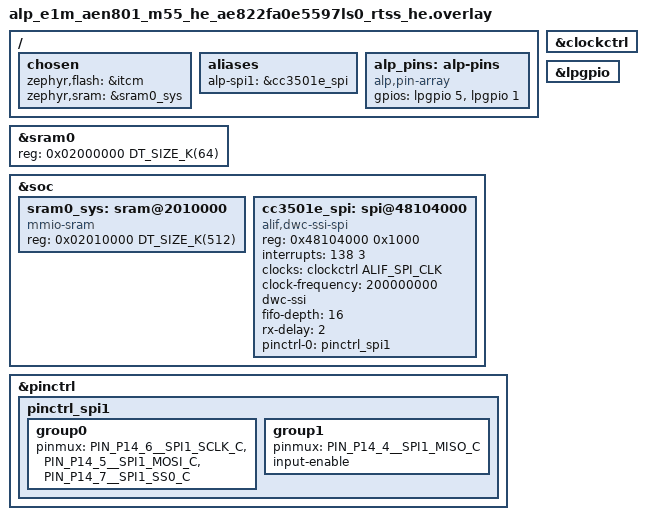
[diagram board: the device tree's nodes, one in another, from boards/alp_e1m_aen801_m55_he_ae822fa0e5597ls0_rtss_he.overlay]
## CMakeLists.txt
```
# SPDX-License-Identifier: Apache-2.0
#
# aen-cc3501e-silent-scan-probe -- tests whether a WIFI_SCAN_START submit
# survives 25 seconds of a completely silent host bus, on the
# E1M-AEN801 (Ensemble E8, M55-HE) bench.
#
# Standalone Zephyr app (no alp_project.py board.yaml flow): build with
#   ZEPHYR_BASE=<zephyr-base> west build \
#     -b alp_e1m_aen801_m55_he/ae822fa0e5597ls0/rtss_he <this-dir> -- \
#     "-DEXTRA_ZEPHYR_MODULES=<alp-sdk>;<hal_alif>"
# Zephyr applies boards/<fully-qualified-board>.overlay by itself.

cmake_minimum_required(VERSION 3.20)

find_package(Zephyr REQUIRED HINTS $ENV{ZEPHYR_BASE})
project(aen_cc3501e_silent_scan_probe LANGUAGES C)

target_sources(app PRIVATE src/main.c)
# The SoM bring-up TEMPLATE (see its own header comment): opens the
# inter-chip SPI1 bridge + WIFI_EN/nRESET, enables the LP-pad output
# drivers pinctrl does not reach, binds the READY line, and runs the
# power + reset sequence. Copied verbatim from aen-cc3501e-command-sweep --
# byte-identical to the copies in every aen-cc3501e-* sibling, same
# reasoning: a copyable template, not a cross-example reach-in.
target_sources(app PRIVATE src/cc3501e_bridge.c)
```

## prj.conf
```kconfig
# SPDX-License-Identifier: Apache-2.0
#
# Bench config for the CC3501E silent-scan probe on the E1M-AEN801 (Alif
# Ensemble E8, M55-HE). See src/main.c for what this app does and why.

# --- Console -----------------------------------------------------------------
# Console: Alp UART console -- E1M edge UART0 (Alif UART5, P3_4/P3_5, 115200
# 8N1, NS16550), the E1M-AEN801 carrier console. The board _defconfig already
# selects it; set explicitly here so the app is self-describing.
CONFIG_SERIAL=y
CONFIG_CONSOLE=y
CONFIG_UART_CONSOLE=y
CONFIG_UART_INTERRUPT_DRIVEN=y
# Serial-less bench? Comment the four lines above and uncomment these to read
# 'ram_console_buf' over SWD instead -- the same toggle every sibling AEN
# bench app documents (see aen-rtc-tick-probe's prj.conf for the fuller note):
# CONFIG_RAM_CONSOLE=y
# CONFIG_RAM_CONSOLE_BUFFER_SIZE=4096
# CONFIG_UART_CONSOLE=n
CONFIG_PRINTK=y

# --- CC3501E bridge (SPI1 + WIFI_EN/nRESET/READY GPIOs) -----------------------
# The host-side chip driver (chips/cc3501e/*.c) plus the two peripheral
# classes it rides on: SPI for the inter-chip link (bus 1 -> the alp-spi1
# alias this app's overlay adds) and GPIO for WIFI_EN / nRESET / READY.
# Kconfig already enforces `depends on SPI && GPIO`; both are set explicitly
# here because this app has no board.yaml `peripherals:` block to generate
# them -- it is a standalone Zephyr app (see scripts/gen_example_alp_conf.py), same as
# every aen-cc3501e-* sibling. CONFIG_ALP_SDK_CHIP_CC3501E pulls in every
# chips/cc3501e/*.c TU, so this app can call cc3501e_ping()/cc3501e_request()/
# cc3501e_wifi_scan() directly with no further Kconfig -- it never routes
# through the portable <alp/wifi.h> backend (CONFIG_ALP_SDK_WIFI_CC3501E),
# which attaches a DIFFERENT set of TUs this app has no use for.
CONFIG_SPI=y
CONFIG_GPIO=y
CONFIG_ALP_SDK=y
CONFIG_ALP_SDK_CHIP_CC3501E=y

# CONFIG_ALP_SDK=y above defaults CONFIG_ALP_SDK_CONSOLE (zephyr/kconfigs/
# core.kconfig) to `y`, which `select`s CONFIG_SHELL -- pulling a `uart:~$`
# shell prompt into the middle of this app's own transcript, AND -- far more
# importantly for THIS app -- installing a shell thread that can poll the
# console/UART on its own schedule. This app's entire premise is a bus that
# nothing at all touches for 25 seconds; a live shell prompt is exactly the
# kind of unrequested background activity that would call the whole result
# into question, even though the shell talks to the E1M UART, not the
# CC3501E's own SPI1 bridge. Turned off explicitly rather than trusted to a
# default.
CONFIG_ALP_SDK_CONSOLE=n

# Headroom for main()'s + the scan-record decode loop's own locals. Matches
# aen-cc3501e-handshake-probe's 4096 (not aen-cc3501e-command-sweep's doubled
# 8192) -- this app carries none of that app's extra BLE_GATT_REGISTER /
# socket-send/recv buffers, just one PING + one raw WIFI_SCAN_START submit +
# one wrapped cc3501e_wifi_scan() call.
#
# THIS VALUE IS ONLY SAFE WHILE src/main.c's cc3501e_t IS static. That type
# embeds several ALP_CC3501E_MAX_PAYLOAD scratch buffers (~32 KB); declared
# automatic it asks main() for a 32908-byte frame, and the overflow check
# fires on the first `sub sp` -- before main()'s first printk, so the app
# dies with no output at all and looks like a dead board. That is not
# hypothetical: it happened on the M55-HE 2026-09-10 and cost a bench run
# (see aen-cc3501e-handshake-probe's own prj.conf).  A green build will not
# catch it; the frame is legal at link time.
CONFIG_MAIN_STACK_SIZE=4096

# Logging ON, deliberately -- a desynced SPI link reports its decisive fault
# via LOG_ERR in the upstream DesignWare SPI driver, and this app is a bench
# diagnostic, not a shipping image. LOG_MODE_MINIMAL keeps it deferred-free
# (no background log-processing thread that would itself be unrequested
# activity during the silence -- see CONFIG_ALP_SDK_CONSOLE=n above for the
# same concern about the shell).
CONFIG_LOG=y
CONFIG_LOG_MODE_MINIMAL=y

# --- Memory/cache: MATCH aen-cc3501e-command-sweep, not just its pin config --
# CONFIG_DCACHE=n for the SoC-wide reason every AEN801 bench app carries it
# (scripts/bench/aen/aen-bench-shared.conf's own header: "the E8 D-cache
# maintenance loop hangs on this silicon"), AND because this app's own
# SCAN_START submit and its two confirming PINGs ride the SAME SPI1 link
# aen-cc3501e-command-sweep and every other AEN801 CC3501E bench app
# measures -- that link's own overlay header documents a DW-SSI master that
# underruns its TX FIFO deasserting its own chip-select mid-frame as
# timing-sensitive to cache-on vs cache-off on this silicon. Running this
# app's transceives faster (cache-on, DTCM) than every other AEN801 bench
# app that has ever measured this link would not be a comparable probe. See
# the app overlay's own header for the matching zephyr,sram retarget this
# depends on.
CONFIG_DCACHE=n

# Measurement app: auto-recovery must stay OFF here (#2126). The driver's
# automatic warm reset fires on a worker-routed op that fails with no reply
# status decoded, which is exactly the shape this sweep measures. A reset
# mid-sweep would change what is being measured (and add ~12-18 s of probe
# time to the elapsed_ms this app reports), so this app keeps the link
# exactly as it found it and reports what it saw.
CONFIG_ALP_SDK_CC3501E_AUTO_RECOVER=n
```

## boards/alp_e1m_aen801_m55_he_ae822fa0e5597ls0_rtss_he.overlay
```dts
/*
 * Copyright (c) 2026 Alp Lab AB
 * SPDX-License-Identifier: Apache-2.0
 *
 * aen-cc3501e-silent-scan-probe -- app overlay for the E1M-AEN801 (Alif
 * Ensemble E8, M55-HE), bench RAM-run via J-Link.
 *
 * Everything below is transcribed from aen-evk-demo's phase-8 overlay block
 * (see that file's own header for the full derivation behind every value
 * here), reused byte-for-byte via aen-cc3501e-command-sweep -- the sibling
 * app this one copies its bring-up template AND its memory placement from
 * (see src/cc3501e_bridge.h and CMakeLists.txt). Trimmed to exactly what
 * the bridge needs: the SoM-internal Alif <-> CC3501E link (SPI1 hardware
 * SS0, the LP-GPIO island carrying WIFI_EN/nRESET, and the READY input),
 * the mandatory bench ITCM retarget, AND (see the block below, deliberately
 * kept even though no other phase's hardware needs it here) the SRAM0
 * system-RAM placement -- this app's own SCAN_START submit and its two
 * confirming PINGs ride that exact SPI1 link, and a faster-than-intended
 * cache/DTCM path would shift the timing on precisely the FIFO-refill axis
 * this app's own 25-second silence exists to hold constant, making the
 * probe not comparable to any other AEN801 bench run. None of aen-evk-demo's
 * other thirteen phases' OWN hardware (PWM LED, SD, Ethernet, I2S/PDM,
 * JPEG) is declared here -- this app touches none of it, and carrying it
 * would only risk a pad conflict with the bridge pins.
 */
#include <zephyr/dt-bindings/pinctrl/alif-ensemble-pinctrl.h>
#include <zephyr/dt-bindings/gpio/gpio.h>

/*
 * ============================================================================
 * SYSTEM-RAM PLACEMENT -- MATCHES aen-evk-demo's phase 8, deliberately
 * ============================================================================
 *
 * This app trims aen-evk-demo's overlay down to exactly the SoM-internal
 * CC3501E bridge (see the block below) -- EXCEPT for this one piece, which
 * it keeps even though nothing else here needs it.
 *
 * aen-evk-demo's own overlay (see ITS header for the full derivation, which
 * this app does not repeat) documents that phase 8's SPI1 FIFO refill --
 * the SAME link this app's Part 2 clocks bulk STREAM_WRITE / SPI1_TRANSFER
 * frames over -- is the one phase sensitive to cache-on vs cache-off timing
 * on this silicon: a DesignWare SSI master that underruns its TX FIFO
 * deasserts its own chip-select mid-frame, and the demo runs from uncached
 * global SRAM0 with CONFIG_DCACHE=n (see prj.conf) rather than the M55's
 * tightly-coupled DTCM specifically to keep that FIFO-refill loop on the
 * same timing this silicon was bench-validated against.
 *
 * A throughput measurement over that link cannot run FASTER than the demo's
 * on precisely the axis the demo's own comment calls out -- that would not
 * be a number anyone else's AEN801 bench run could be compared against, it
 * would be measuring a different link. So this app carries the same
 * retarget, even though (unlike the demo) it has no Ethernet DMA rings or
 * JPEG buffers that need SRAM0 for their own reasons -- one disjoint 512 KiB
 * window is more than this app's own footprint needs, but a narrower
 * carve-out would only add a second constant to keep in sync with the demo
 * for no behavioural benefit.
 */
&sram0 {
	reg = <0x02000000 DT_SIZE_K(64)>;
};

&soc {
	/* Plain "mmio-sram", NOT "zephyr,memory-region" -- see aen-evk-demo's
	 * overlay for why a second memory-region-compatible node here would
	 * alias the linker region instead of extending it. */
	sram0_sys: sram@2010000 {
		compatible = "mmio-sram";
		reg = <0x02010000 DT_SIZE_K(512)>;
	};
};

/*
 * MANDATORY bench RAM-run retarget: run from ITCM so J-Link can loadbin+run
 * without programming MRAM, and drop the MCUboot code-partition fixup.
 * PATH-REFERENCE form (&itcm), NOT the <&itcm> phandle-array form -- the
 * phandle-array form yields CONFIG_FLASH_SIZE=0 and the image overflows the
 * (empty) FLASH region at link time. System RAM (zephyr,sram) is retargeted
 * separately, to &sram0_sys above -- see that block's header.
 */
/ {
	chosen {
		zephyr,flash = &itcm;
		/delete-property/ zephyr,code-partition;
		zephyr,sram = &sram0_sys;
	};
};

/*
 * ============================================================================
 * The SoM-internal Alif <-> CC3501E Wi-Fi/BLE bridge
 * ============================================================================
 *
 *     net          Alif pad       dir   CC3501E pad
 *     ----------   ------------   ---   ---------------------
 *     WIFI_EN      P15_5          out   (supply gate)
 *     E_WIFI.NRST  P15_1_FLEX     out   (reset)
 *     SPI1.SCK     P14_6          out   GPIO_27 (CC35 SPI0 slave)
 *     SPI1.MOSI    P14_5          out   GPIO_28
 *     SPI1.MISO    P14_4          in    GPIO_29
 *     SPI1.SS0     P14_7          out   CC35 SPI0 CSN
 *
 * READY (CC35 GPIO_17) is deliberately left off this table: on the R2
 * module this app targets it is NOT wired to Alif P2_6 -- P2_6 is E1M pad
 * AH7 / I2S1_SCLK (the EVK's Arduino CK_RST), a DIFFERENT net from GPIO_17
 * / E1M pad G3.  See the P2_6 comment further down and
 * chips/cc3501e/cc3501e_core.c's cc3501e_reply_gate() comment for the bench
 * evidence and how a board that genuinely wires it can opt in.
 *
 * SoM-INTERNAL fact (metadata/e1m_modules/aen/inter-chip.tsv), not an E1M
 * edge pad -- hence an app overlay, not the board tree.
 */
&pinctrl {
	/*
	 * SPI1 master on P14_6 (SCK) / P14_5 (MOSI) / P14_4 (MISO), plus the
	 * hardware SS0 chip-select on P14_7. SS0 is the dwc-ssi peripheral's
	 * OWN select -- not a GPIO bodge, not CS-less, not static-low: the
	 * master asserts and deasserts it per transfer, which is exactly what
	 * frames each phase of the bridge's request/reply exchange. Do NOT
	 * add cs-gpios here; that installs a software CS and breaks the
	 * framing the firmware side is built around.
	 *
	 * input-enable on MISO because on this SoC a pad's INPUT BUFFER is a
	 * PADCTRL bit that only pinctrl sets -- without it the pad never
	 * senses what the slave drives.
	 */
	pinctrl_spi1: pinctrl_spi1 {
		group0 {
			pinmux = <PIN_P14_6__SPI1_SCLK_C>, <PIN_P14_5__SPI1_MOSI_C>,
				 <PIN_P14_7__SPI1_SS0_C>;
		};
		group1 {
			pinmux = <PIN_P14_4__SPI1_MISO_C>;
			input-enable;
		};

	};
};

/* P2_6 (E1M AH7 / I2S1_SCLK) is NOT the CC3501E READY net on the R2 module this
 * bridge targets -- it is E1M pad AH7 / I2S1_SCLK, which the E1M EVK
 * carrier repurposes as the Arduino header's CK_RST (metadata/boards/
 * e1m-evk.yaml); the real READY net lands on E1M pad G3 / IO16 instead
 * (metadata/e1m_modules/aen/from-cc3501e.tsv). This app therefore does not
 * mux or input-enable P2_6, and does not wire fw->ready_pin -- see
 * src/cc3501e_bridge.c and chips/cc3501e/cc3501e_core.c's cc3501e_reply_gate()
 * comment. A board (or a hand-reworked r1 unit) that genuinely wires GPIO17
 * to P2_6 can opt back in: add a pinctrl group muxing PIN_P2_6__GPIO with
 * input-enable (applied inside pinctrl_spi1's single init pass, not a
 * standalone runtime one -- a second pinctrl pass after SPI1 is up killed
 * the bridge on silicon, aen-evk-demo bench-measured), enable &gpio2, add
 * an alp_pins entry for it, and set fw->ready_pin in
 * cc3501e_bridge_bringup().

/*
 * DWC_ssi SPI1 (AHB) -- the on-SoM CC3501E inter-chip link. Deliberately not
 * in ensemble_e8_peripherals.dtsi (which declares only the customer-facing
 * edge SPI0), so the consuming app declares it. reg 0x48104000 = the SPI1
 * base (+0x1000 per instance from spi0's 0x48103000).
 *
 * clock-frequency is REQUIRED, not decorative: without it spi_dw_alif's
 * configure takes the clock-control path, which fails -EINVAL for the
 * gateless dummy ALIF_SPI_CLK, and every transceive then returns
 * ALP_ERR_INVAL at zero SCLK. 200 MHz is the real SSI functional clock (E8
 * HWRM); BAUDR = clock-frequency / freq_hz, and cc3501e_bridge.h asks for
 * 25 MHz = /8.
 *
 * rx-delay: NOT what clocks the link -- src/cc3501e_bridge.c pokes
 * 0x48104000+0xf0 with CC3501E_BRIDGE_RX_SAMPLE_DLY right after
 * alp_spi_open() returns, and that constant (silicon-measured, see that
 * file's header) is what the bridge actually runs at. Kept at <2> anyway
 * because the poke is wrapped in `#if CC3501E_BRIDGE_RX_SAMPLE_DLY > 0` --
 * setting the constant to 0 does not mean "no delay", it means this
 * property is what survives.
 */
&clockctrl {
	status = "okay";
};

&soc {
	cc3501e_spi: spi@48104000 {
		compatible = "alif,dwc-ssi-spi";
		#address-cells = <1>;
		#size-cells = <0>;
		reg = <0x48104000 0x1000>;
		interrupts = <138 3>; /* BENCH-TBD: confirm SPI1 IRQ, same as aen-evk-demo */
		clocks = <&clockctrl ALIF_SPI_CLK>;
		clock-frequency = <200000000>;
		dwc-ssi;
		fifo-depth = <16>;
		rx-delay = <2>;
		pinctrl-0 = <&pinctrl_spi1>;
		pinctrl-names = "default";
		status = "okay";
	};
};

/*
 * The LP-GPIO island carries WIFI_EN (P15_5) and E_WIFI.NRST (P15_1_FLEX).
 * No pinctrl group is needed for their mux: P15_x function 0 -- the reset
 * default -- already IS LPGPIO. Turning the pads' OUTPUT DRIVERS on is a
 * separate matter and not a devicetree fact at all; see the raw PADCTRL
 * write in src/cc3501e_bridge.c and the comment above it.
 */
&lpgpio {
	status = "okay";
};

/ {
	aliases {
		/* bus_id 1 in alp_spi_open() -> this controller. */
		alp-spi1 = &cc3501e_spi;
	};

	/*
	 * Compact 2-entry control array for the SoM-internal CC3501E control
	 * nets, in the order cc3501e_bridge.h's CC3501E_BRIDGE_PIN_* indices
	 * expect. These are NOT E1M edge pads, so this app does not use the
	 * 52-slot positional E1M map; a production board file appends
	 * SoM-internal control nets after the E1M pad slots. No READY entry
	 * here -- see the P2_6 comment above &gpio2's removal further up.
	 *
	 * There must be exactly ONE "alp,pin-array" node in the tree -- a
	 * second one broke pin resolution outright on the aen-evk-demo bench
	 * (2026-08-26): the bridge failed as if WIFI_EN were absent, which
	 * reads like a hardware fault and is not one.
	 */
	alp_pins: alp-pins {
		compatible = "alp,pin-array";
		gpios = <&lpgpio 5 GPIO_ACTIVE_HIGH>, /* [0] WIFI_EN     (P15_5)      */
			<&lpgpio 1 GPIO_ACTIVE_HIGH>; /* [1] E_WIFI.NRST (P15_1_FLEX) */
	};
};
```

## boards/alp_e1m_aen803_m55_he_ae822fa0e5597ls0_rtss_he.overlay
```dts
/*
 * Copyright (c) 2026 Alp Lab AB
 * SPDX-License-Identifier: Apache-2.0
 *
 * aen-cc3501e-silent-scan-probe -- app overlay for the E1M-AEN803 (Alif
 * Ensemble E8, M55-HE), bench RAM-run via J-Link.
 *
 * Everything below is transcribed from aen-evk-demo's phase-8 overlay block
 * (see that file's own header for the full derivation behind every value
 * here), reused byte-for-byte via aen-cc3501e-command-sweep -- the sibling
 * app this one copies its bring-up template AND its memory placement from
 * (see src/cc3501e_bridge.h and CMakeLists.txt). Trimmed to exactly what
 * the bridge needs: the SoM-internal Alif <-> CC3501E link (SPI1 hardware
 * SS0, the LP-GPIO island carrying WIFI_EN/nRESET, and the READY input),
 * the mandatory bench ITCM retarget, AND (see the block below, deliberately
 * kept even though no other phase's hardware needs it here) the SRAM0
 * system-RAM placement -- this app's own SCAN_START submit and its two
 * confirming PINGs ride that exact SPI1 link, and a faster-than-intended
 * cache/DTCM path would shift the timing on precisely the FIFO-refill axis
 * this app's own 25-second silence exists to hold constant, making the
 * probe not comparable to any other AEN803 bench run. None of aen-evk-demo's
 * other thirteen phases' OWN hardware (PWM LED, SD, Ethernet, I2S/PDM,
 * JPEG) is declared here -- this app touches none of it, and carrying it
 * would only risk a pad conflict with the bridge pins.
 */
#include <zephyr/dt-bindings/pinctrl/alif-ensemble-pinctrl.h>
#include <zephyr/dt-bindings/gpio/gpio.h>

/*
 * ============================================================================
 * SYSTEM-RAM PLACEMENT -- MATCHES aen-evk-demo's phase 8, deliberately
 * ============================================================================
 *
 * This app trims aen-evk-demo's overlay down to exactly the SoM-internal
 * CC3501E bridge (see the block below) -- EXCEPT for this one piece, which
 * it keeps even though nothing else here needs it.
 *
 * aen-evk-demo's own overlay (see ITS header for the full derivation, which
 * this app does not repeat) documents that phase 8's SPI1 FIFO refill --
 * the SAME link this app's Part 2 clocks bulk STREAM_WRITE / SPI1_TRANSFER
 * frames over -- is the one phase sensitive to cache-on vs cache-off timing
 * on this silicon: a DesignWare SSI master that underruns its TX FIFO
 * deasserts its own chip-select mid-frame, and the demo runs from uncached
 * global SRAM0 with CONFIG_DCACHE=n (see prj.conf) rather than the M55's
 * tightly-coupled DTCM specifically to keep that FIFO-refill loop on the
 * same timing this silicon was bench-validated against.
 *
 * A throughput measurement over that link cannot run FASTER than the demo's
 * on precisely the axis the demo's own comment calls out -- that would not
 * be a number anyone else's AEN803 bench run could be compared against, it
 * would be measuring a different link. So this app carries the same
 * retarget, even though (unlike the demo) it has no Ethernet DMA rings or
 * JPEG buffers that need SRAM0 for their own reasons -- one disjoint 512 KiB
 * window is more than this app's own footprint needs, but a narrower
 * carve-out would only add a second constant to keep in sync with the demo
 * for no behavioural benefit.
 */
&sram0 {
	reg = <0x02000000 DT_SIZE_K(64)>;
};

&soc {
	/* Plain "mmio-sram", NOT "zephyr,memory-region" -- see aen-evk-demo's
	 * overlay for why a second memory-region-compatible node here would
	 * alias the linker region instead of extending it. */
	sram0_sys: sram@2010000 {
		compatible = "mmio-sram";
		reg = <0x02010000 DT_SIZE_K(512)>;
	};
};

/*
 * MANDATORY bench RAM-run retarget: run from ITCM so J-Link can loadbin+run
 * without programming MRAM, and drop the MCUboot code-partition fixup.
 * PATH-REFERENCE form (&itcm), NOT the <&itcm> phandle-array form -- the
 * phandle-array form yields CONFIG_FLASH_SIZE=0 and the image overflows the
 * (empty) FLASH region at link time. System RAM (zephyr,sram) is retargeted
 * separately, to &sram0_sys above -- see that block's header.
 */
/ {
	chosen {
		zephyr,flash = &itcm;
		/delete-property/ zephyr,code-partition;
		zephyr,sram = &sram0_sys;
	};
};

/*
 * ============================================================================
 * The SoM-internal Alif <-> CC3501E Wi-Fi/BLE bridge
 * ============================================================================
 *
 *     net          Alif pad       dir   CC3501E pad
 *     ----------   ------------   ---   ---------------------
 *     WIFI_EN      P15_5          out   (supply gate)
 *     E_WIFI.NRST  P15_1_FLEX     out   (reset)
 *     SPI1.SCK     P14_6          out   GPIO_27 (CC35 SPI0 slave)
 *     SPI1.MOSI    P14_5          out   GPIO_28
 *     SPI1.MISO    P14_4          in    GPIO_29
 *     SPI1.SS0     P14_7          out   CC35 SPI0 CSN
 *
 * READY (CC35 GPIO_17) is deliberately left off this table: on the R2
 * module this app targets it is NOT wired to Alif P2_6 -- P2_6 is E1M pad
 * AH7 / I2S1_SCLK (the EVK's Arduino CK_RST), a DIFFERENT net from GPIO_17
 * / E1M pad G3.  See the P2_6 comment further down and
 * chips/cc3501e/cc3501e_core.c's cc3501e_reply_gate() comment for the bench
 * evidence and how a board that genuinely wires it can opt in.
 *
 * SoM-INTERNAL fact (metadata/e1m_modules/aen/inter-chip.tsv), not an E1M
 * edge pad -- hence an app overlay, not the board tree.
 */
&pinctrl {
	/*
	 * SPI1 master on P14_6 (SCK) / P14_5 (MOSI) / P14_4 (MISO), plus the
	 * hardware SS0 chip-select on P14_7. SS0 is the dwc-ssi peripheral's
	 * OWN select -- not a GPIO bodge, not CS-less, not static-low: the
	 * master asserts and deasserts it per transfer, which is exactly what
	 * frames each phase of the bridge's request/reply exchange. Do NOT
	 * add cs-gpios here; that installs a software CS and breaks the
	 * framing the firmware side is built around.
	 *
	 * input-enable on MISO because on this SoC a pad's INPUT BUFFER is a
	 * PADCTRL bit that only pinctrl sets -- without it the pad never
	 * senses what the slave drives.
	 */
	pinctrl_spi1: pinctrl_spi1 {
		group0 {
			pinmux = <PIN_P14_6__SPI1_SCLK_C>, <PIN_P14_5__SPI1_MOSI_C>,
				 <PIN_P14_7__SPI1_SS0_C>;
		};
		group1 {
			pinmux = <PIN_P14_4__SPI1_MISO_C>;
			input-enable;
		};

	};
};

/* P2_6 (E1M AH7 / I2S1_SCLK) is NOT the CC3501E READY net on the R2 module this
 * bridge targets -- it is E1M pad AH7 / I2S1_SCLK, which the E1M EVK
 * carrier repurposes as the Arduino header's CK_RST (metadata/boards/
 * e1m-evk.yaml); the real READY net lands on E1M pad G3 / IO16 instead
 * (metadata/e1m_modules/aen/from-cc3501e.tsv). This app therefore does not
 * mux or input-enable P2_6, and does not wire fw->ready_pin -- see
 * src/cc3501e_bridge.c and chips/cc3501e/cc3501e_core.c's cc3501e_reply_gate()
 * comment. A board (or a hand-reworked r1 unit) that genuinely wires GPIO17
 * to P2_6 can opt back in: add a pinctrl group muxing PIN_P2_6__GPIO with
 * input-enable (applied inside pinctrl_spi1's single init pass, not a
 * standalone runtime one -- a second pinctrl pass after SPI1 is up killed
 * the bridge on silicon, aen-evk-demo bench-measured), enable &gpio2, add
 * an alp_pins entry for it, and set fw->ready_pin in
 * cc3501e_bridge_bringup().

/*
 * DWC_ssi SPI1 (AHB) -- the on-SoM CC3501E inter-chip link. Deliberately not
 * in ensemble_e8_peripherals.dtsi (which declares only the customer-facing
 * edge SPI0), so the consuming app declares it. reg 0x48104000 = the SPI1
 * base (+0x1000 per instance from spi0's 0x48103000).
 *
 * clock-frequency is REQUIRED, not decorative: without it spi_dw_alif's
 * configure takes the clock-control path, which fails -EINVAL for the
 * gateless dummy ALIF_SPI_CLK, and every transceive then returns
 * ALP_ERR_INVAL at zero SCLK. 200 MHz is the real SSI functional clock (E8
 * HWRM); BAUDR = clock-frequency / freq_hz, and cc3501e_bridge.h asks for
 * 25 MHz = /8.
 *
 * rx-delay: NOT what clocks the link -- src/cc3501e_bridge.c pokes
 * 0x48104000+0xf0 with CC3501E_BRIDGE_RX_SAMPLE_DLY right after
 * alp_spi_open() returns, and that constant (silicon-measured, see that
 * file's header) is what the bridge actually runs at. Kept at <2> anyway
 * because the poke is wrapped in `#if CC3501E_BRIDGE_RX_SAMPLE_DLY > 0` --
 * setting the constant to 0 does not mean "no delay", it means this
 * property is what survives.
 */
&clockctrl {
	status = "okay";
};

&soc {
	cc3501e_spi: spi@48104000 {
		compatible = "alif,dwc-ssi-spi";
		#address-cells = <1>;
		#size-cells = <0>;
		reg = <0x48104000 0x1000>;
		interrupts = <138 3>; /* BENCH-TBD: confirm SPI1 IRQ, same as aen-evk-demo */
		clocks = <&clockctrl ALIF_SPI_CLK>;
		clock-frequency = <200000000>;
		dwc-ssi;
		fifo-depth = <16>;
		rx-delay = <2>;
		pinctrl-0 = <&pinctrl_spi1>;
		pinctrl-names = "default";
		status = "okay";
	};
};

/*
 * The LP-GPIO island carries WIFI_EN (P15_5) and E_WIFI.NRST (P15_1_FLEX).
 * No pinctrl group is needed for their mux: P15_x function 0 -- the reset
 * default -- already IS LPGPIO. Turning the pads' OUTPUT DRIVERS on is a
 * separate matter and not a devicetree fact at all; see the raw PADCTRL
 * write in src/cc3501e_bridge.c and the comment above it.
 */
&lpgpio {
	status = "okay";
};

/ {
	aliases {
		/* bus_id 1 in alp_spi_open() -> this controller. */
		alp-spi1 = &cc3501e_spi;
	};

	/*
	 * Compact 2-entry control array for the SoM-internal CC3501E control
	 * nets, in the order cc3501e_bridge.h's CC3501E_BRIDGE_PIN_* indices
	 * expect. These are NOT E1M edge pads, so this app does not use the
	 * 52-slot positional E1M map; a production board file appends
	 * SoM-internal control nets after the E1M pad slots. No READY entry
	 * here -- see the P2_6 comment above &gpio2's removal further up.
	 *
	 * There must be exactly ONE "alp,pin-array" node in the tree -- a
	 * second one broke pin resolution outright on the aen-evk-demo bench
	 * (2026-08-26): the bridge failed as if WIFI_EN were absent, which
	 * reads like a hardware fault and is not one.
	 */
	alp_pins: alp-pins {
		compatible = "alp,pin-array";
		gpios = <&lpgpio 5 GPIO_ACTIVE_HIGH>, /* [0] WIFI_EN     (P15_5)      */
			<&lpgpio 1 GPIO_ACTIVE_HIGH>; /* [1] E_WIFI.NRST (P15_1_FLEX) */
	};
};
```

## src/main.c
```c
/*
 * Copyright (c) 2026 Alp Lab AB
 * SPDX-License-Identifier: Apache-2.0
 *
 * aen-cc3501e-silent-scan-probe -- tests whether a single WIFI_SCAN_START
 * submit survives 25 seconds of a completely silent host bus, for the
 * E1M-AEN801 (Alif Ensemble E8, M55-HE), bench RAM-run via J-Link.
 *
 * WHY THIS APP EXISTS -- separating two readings of the WIFI_SCAN_START wedge
 * ------------------------------------------------------------------------
 * WIFI_SCAN_START wedges the CC3501E bridge on this bench. Root-cause
 * analysis has narrowed it to two readings every measurement so far is
 * equally consistent with:
 *
 *   B.     The firmware brackets its station role-up with a bridge quiesce,
 *          and the quiesce hangs. The quiesce cancels an armed
 *          callback-mode transfer, and the firmware's own notes record
 *          three separate bench occasions where doing that WHILE THE HOST
 *          WAS CLOCKING THE BUS locked the core up. The one configuration
 *          in which it ever worked was at boot, with no host traffic to
 *          disrupt.
 *   Other. The heavy radio operation itself does not return within its
 *          bound, in which case host traffic is irrelevant.
 *
 * These separate cleanly on one observation: under B, if the host puts
 * NOTHING AT ALL on the bus while the firmware does its radio work, the
 * cancel operates on an idle armed transfer with no host bytes in flight --
 * the same conditions under which it historically worked -- so the radio
 * work completes, the bridge re-initialises, and the link comes back. Under
 * the OTHER reading the bus stays dead regardless of how quiet the host is.
 *
 * The standard driver call (@ref cc3501e_wifi_scan) cannot test this: it
 * submits and then polls status every 50 ms for its whole budget, and THAT
 * POLLING IS THE TRAFFIC UNDER SUSPICION. This app instead submits once
 * through the raw @ref cc3501e_request path (the same submit-once shape
 * @ref cc3501e_wifi_ap_start uses against WIFI_AP_START,
 * chips/cc3501e/cc3501e_wifi.c, around lines 513-514) and then issues
 * NOTHING AT ALL -- not even a status poll -- for 25 seconds. See STEP 3
 * below for exactly what "nothing at all" means and why it is safe to trust.
 *
 * THE SILENCE IS THE EXPERIMENT. Any instrumentation added to this file
 * that clocks the bus during STEP 3's k_msleep() destroys the result -- see
 * that step's own comment before touching it.
 *
 * WHAT THIS RUN CANNOT PROVE, AND WHEN IT SAYS SO
 * ------------------------------------------------
 * The submit in STEP 2 has to actually land on the wire before the silence
 * means anything: if it comes back as an I/O error or a timeout rather than
 * the expected busy-style acknowledgement, the submit frame itself did not
 * complete, and 25 seconds of silence afterwards proves nothing about
 * either reading above. This app checks for exactly that and prints
 * `=== VOID RUN ===` instead of proceeding -- see STEP 2 below.
 *
 * CREDENTIALS -- none needed
 * ---------------------------
 * A scan takes no SSID or passphrase, and that is part of why it is the
 * right probe here: unlike aen-cc3501e-wedge-postmortem's WIFI_CONNECT_STA
 * repro, this app needs no build-time credential defines and commits none.
 *
 * Build target: alp_e1m_aen801_m55_he/ae822fa0e5597ls0/rtss_he -- see this
 * app's README.md for the full west build invocation and the overlay's own
 * header for why the SRAM0 memory placement and CONFIG_DCACHE=n are
 * load-bearing, not decorative: this app's own submit + both PINGs ride the
 * identical SPI1 link every other AEN801 CC3501E bench app measures, and a
 * faster cache-on/DTCM path would shift timing on precisely the axis the
 * 25-second silence exists to hold constant.
 */

#include <stdbool.h>
#include <stdint.h>

#include <zephyr/kernel.h>

#include "alp/chips/cc3501e.h"
#include "alp/peripheral.h" /* alp_status_name() */
#include "cc3501e_bridge.h" /* cc3501e_bridge_bringup() -- the SoM bring-up template */

/*
 * ======================================================================
 * Tunables
 * ======================================================================
 */

/* Same shape as every aen-cc3501e-* sibling's own PING retry loop (e.g.
 * aen-cc3501e-wedge-postmortem's WEDGEPM_PING_RETRIES): the bring-up call
 * this app makes already waited out its own boot budget once, so this loop
 * only absorbs residual ramp/boot jitter. Reused for both PINGs this app
 * issues (STEP 1's bring-up confirmation and STEP 4's post-silence PING). */
#define SSCANPROBE_PING_RETRIES 25u
#define SSCANPROBE_PING_GAP_MS  200u

/* Mirrors CC3501E_REQ_TMO_MS (chips/cc3501e/cc3501e_internal.h line 19) --
 * the SAME per-attempt reply-wait budget cc3501e_wifi_ap_start() passes to
 * its own single-shot, non-retried cc3501e_request() call (chips/cc3501e/
 * cc3501e_wifi.c, around lines 513-514), the shape this app's own
 * WIFI_SCAN_START submit copies. Not #include'd from the driver's private
 * cc3501e_internal.h -- that header is explicitly "not installed, not part
 * of the public API" (its own file header) -- so this app carries its own
 * copy of the value, same as every aen-cc3501e-* sibling defines its own
 * tunables rather than reaching into driver internals. */
#define SSCANPROBE_SUBMIT_TMO_MS 100u

/*
 * THE LOAD-BEARING CONSTANT. How long STEP 3 issues NOTHING AT ALL on the
 * bus after the STEP 2 submit is acknowledged -- not a status poll, not a
 * ping, not a diagnostic read. This is the entire experiment (see this
 * file's own header): a completely silent bus during the firmware's radio
 * work is the one condition mechanism B's own bench notes record as
 * historically safe. Do NOT shrink this hunting for a faster run, and do
 * NOT add any driver call inside the k_msleep() this constant bounds -- see
 * STEP 3's own comment. */
#define SSCANPROBE_SILENCE_MS 25000u

/* Step 5's ordinary scan budget -- the task's own figure, generously above
 * every aen-cc3501e-* sibling's connect-family budget derivation (40 s of
 * association+DHCP headroom, see aen-cc3501e-wedge-postmortem's
 * WEDGEPM_QUIET_WAIT_MS comment for that derivation) because if the role
 * really did latch from STEP 2's submit, this second scan performs no
 * role-up at all and should return quickly; if it did not, this budget is
 * generous enough not to call a slow-but-alive scan a failure. */
#define SSCANPROBE_SCAN_TIMEOUT_MS 40000u

/* Scan-record capacity for STEP 5's normal wrapper call. Matches
 * aen-cc3501e-companion-tour's own TOUR_SCAN_MAX -- generous for a bench
 * scan, not a hard protocol limit. */
#define SSCANPROBE_SCAN_MAX 16u

/*
 * ======================================================================
 * PING helper -- same shape as every aen-cc3501e-* sibling's own PING loop.
 * ======================================================================
 */

/** PING with a bounded retry loop, printing the attempt count. @p label
 *  prefixes the console line so the transcript names which step's PING
 *  this is (STEP 1's bring-up confirmation vs STEP 4's post-silence one). */
static bool sscanprobe_ping_wait(cc3501e_t *fw, const char *label)
{
	for (unsigned i = 0u; i < SSCANPROBE_PING_RETRIES; i++) {
		if (cc3501e_ping(fw) == ALP_OK) {
			printk("%s: PING ok after %u attempt%s\n", label, i + 1u, (i == 0u) ? "" : "s");
			return true;
		}
		k_msleep(SSCANPROBE_PING_GAP_MS);
	}
	printk("%s: PING never answered after %u attempts\n", label, (unsigned)SSCANPROBE_PING_RETRIES);
	return false;
}

/* ---------------------------------------------------------------------- */

int main(void)
{
	printk("\n=== AEN801 CC3501E silent-scan probe ===\n");

	/*
	 * STATIC, explicitly zero-initialised cc3501e_t -- same discipline as
	 * every aen-cc3501e-* sibling, for the identical reason: this type
	 * embeds several ALP_CC3501E_MAX_PAYLOAD scratch buffers (~32 KB
	 * total). Declared automatic it asks main() for a multi-kilobyte
	 * stack frame, and Zephyr's stack-overflow check fires on the very
	 * first `sub sp` -- before this function's own first printk. Measured
	 * on the M55-HE 2026-09-10 by aen-cc3501e-handshake-probe (32908-byte
	 * frame); this app inherits the same fix rather than rediscovering
	 * the same failure.
	 */
	static cc3501e_t fw = { 0 };

	/*
	 * ---------------------------------------------------------------
	 * STEP 1 -- bring the bridge up, then confirm with a PING, exactly
	 * like every aen-cc3501e-* sibling's own bring-up (same
	 * src/cc3501e_bridge.{c,h} template, same overlay).
	 * ---------------------------------------------------------------
	 */
	alp_status_t rc = cc3501e_bridge_bringup(&fw);
	printk("STEP 1: bridge bring-up (WIFI_EN high, nRESET pulsed, SPI1 @ %u Hz) -> %d (%s)\n",
	       (unsigned)CC3501E_BRIDGE_SPI_FREQ_HZ,
	       (int)rc,
	       alp_status_name(rc));
	if (rc != ALP_OK) {
		printk("  ** bring-up did NOT return ALP_OK -- nothing downstream of it can work. "
		       "Stopping here. **\n");
		return 0;
	}
	if (!sscanprobe_ping_wait(&fw, "STEP 1")) {
		printk("  ** PING never answered -- check WIFI_EN power, the SPI1 pinmux, and that "
		       "the CC3501E is running its firmware. Stopping here. **\n");
		return 0;
	}

	/*
	 * ---------------------------------------------------------------
	 * STEP 2 -- submit WIFI_SCAN_START EXACTLY ONCE, through the raw
	 * cc3501e_request() path rather than the polling wrapper
	 * (cc3501e_wifi_scan(), which re-issues WIFI_SCAN_START on a 50 ms
	 * poll cadence for its whole budget -- see this file's own header
	 * for why that polling is exactly the traffic under suspicion here,
	 * and must not run before the silence in STEP 3).
	 *
	 * This follows cc3501e_wifi_ap_start()'s own submit-once shape
	 * (chips/cc3501e/cc3501e_wifi.c, around lines 513-514): a single,
	 * non-retried cc3501e_request() call with no reply buffer (the scan
	 * result payload is not wanted here -- STEP 5's normal wrapper reads
	 * it later, once the role is confirmed latched) and a fixed
	 * SSCANPROBE_SUBMIT_TMO_MS budget.
	 * ---------------------------------------------------------------
	 */
	printk("\nSTEP 2: submit WIFI_SCAN_START once (raw cc3501e_request(), no polling)\n");
	alp_status_t submit_rc = cc3501e_request(
	    &fw, ALP_CC3501E_CMD_WIFI_SCAN_START, NULL, 0, NULL, 0, NULL, SSCANPROBE_SUBMIT_TMO_MS);
	printk(
	    "STEP 2: WIFI_SCAN_START submit -> %d (%s)\n", (int)submit_rc, alp_status_name(submit_rc));

	/*
	 * The busy-style acknowledgement (ALP_ERR_BUSY, wire RESP_ERR_BUSY --
	 * see cc3501e_reply_verdict(), chips/cc3501e/cc3501e_core.c) is the
	 * ONLY outcome this app treats as "the job was accepted": it means the
	 * firmware's worker actually queued the scan. An I/O error or a
	 * timeout means the submit frame itself did not complete -- the
	 * firmware never got the request, or the reply never came back
	 * readable -- and the 25-second silence that follows would then be
	 * silence around NOTHING, proving neither reading in this file's own
	 * header. This app does not try to guess past that: it declares the
	 * run VOID and stops, rather than let a silent bus after a failed
	 * submit be misread as "the link survived the silence".
	 */
	if (submit_rc != ALP_ERR_BUSY) {
		printk("\n=== VOID RUN ===\n"
		       "STEP 2's submit did NOT get the expected busy-style acknowledgement "
		       "(ALP_ERR_BUSY / RESP_ERR_BUSY) -- it returned %s (%d) instead. The submit "
		       "frame itself did not complete, so this run proves NOTHING about either "
		       "reading in this app's own file header: not that the link survives a silent "
		       "bus during the radio work, and not that it doesn't. Stopping here rather "
		       "than continue into a silence whose premise already failed.\n",
		       alp_status_name(submit_rc),
		       (int)submit_rc);
		return 0;
	}
	printk("STEP 2: accepted (busy-style ack) -- the firmware's scan worker is now running\n");

	/*
	 * ---------------------------------------------------------------
	 * STEP 3 -- THE EXPERIMENT. Issue NOTHING AT ALL for 25 seconds:
	 * no status poll, no ping, no diagnostic read, no driver call of
	 * any kind. See this file's own header for why this exact
	 * condition is what separates the two live readings of the wedge.
	 *
	 * DO NOT ADD ANY CALL BETWEEN THIS COMMENT AND THE k_msleep() BELOW.
	 * Any cc3501e_* call here -- even a read-only one -- clocks the SPI1
	 * bus and reintroduces the exact host traffic this probe exists to
	 * rule out; it would not be a stronger test, it would be a
	 * DIFFERENT, uninformative one indistinguishable from the polling
	 * wrapper's own 50 ms cadence this app was built specifically to
	 * avoid.
	 *
	 * The driver's own housekeeping must not run either, and it does
	 * not: chips/cc3501e/ and the backends it attaches (src/backends/)
	 * carry no k_timer, no k_work / k_work_delayable, and no periodic
	 * poll of any kind (grepped for k_timer / k_work_schedule /
	 * k_work_submit / k_work_init / K_WORK_DELAYABLE_DEFINE /
	 * K_TIMER_DEFINE across both trees, 2026-09-11 -- none matched
	 * outside src/backends/power/zephyr_pm_policy.c, which is an
	 * unrelated PM-policy TU this app's prj.conf never pulls in). Every
	 * request this driver issues is caller-driven; nothing left armed
	 * by STEP 1's bring-up or STEP 2's submit clocks the bus on its own
	 * while this k_msleep() runs. CONFIG_ALP_SDK_CONSOLE=n (prj.conf)
	 * additionally keeps the shell thread out of existence for the same
	 * reason, even though the shell would talk to the E1M UART console,
	 * not this SPI1 link -- unrequested background activity of ANY kind
	 * during this window is worth eliminating on principle here.
	 * ---------------------------------------------------------------
	 */
	printk("\nSTEP 3: silence -- issuing NOTHING for %u ms (no polling, no ping, no "
	       "diagnostic read). This silence is the experiment; see this file's own header.\n",
	       (unsigned)SSCANPROBE_SILENCE_MS);
	k_msleep(SSCANPROBE_SILENCE_MS);
	printk("STEP 3: silence complete\n");

	/*
	 * ---------------------------------------------------------------
	 * STEP 4 -- a single PING. This is the first thing to touch the bus
	 * since STEP 2's submit.
	 * ---------------------------------------------------------------
	 */
	printk("\nSTEP 4: single confirming PING (first bus activity since the STEP 2 submit)\n");
	bool survived_silence = sscanprobe_ping_wait(&fw, "STEP 4");

	/*
	 * ---------------------------------------------------------------
	 * STEP 5 -- a normal scan through the ordinary polling wrapper, now
	 * that the silence is over. If the role latched from STEP 2's
	 * submit, the firmware should already have scan results cached and
	 * this call performs no role-up of its own -- it should return
	 * promptly with records rather than block for the whole budget.
	 * ---------------------------------------------------------------
	 */
	printk("\nSTEP 5: normal Wi-Fi scan (cc3501e_wifi_scan(), %u ms budget)\n",
	       (unsigned)SSCANPROBE_SCAN_TIMEOUT_MS);
	static cc3501e_scan_record_t records[SSCANPROBE_SCAN_MAX];
	size_t                       count = 0;
	alp_status_t                 scan_rc =
	    cc3501e_wifi_scan(&fw, records, SSCANPROBE_SCAN_MAX, &count, SSCANPROBE_SCAN_TIMEOUT_MS);
	printk("STEP 5: cc3501e_wifi_scan() -> %d (%s), record count = %u\n",
	       (int)scan_rc,
	       alp_status_name(scan_rc),
	       (unsigned)count);
	bool got_records = (scan_rc == ALP_OK) && (count > 0u);
	for (size_t i = 0; i < count; i++) {
		const cc3501e_scan_record_t *r = &records[i];
		printk("STEP 5:   [%2u] ssid=\"%s\" sec=%s rssi=%d dBm channel=%u\n",
		       (unsigned)i,
		       r->ssid,
		       cc3501e_wifi_sec_name(r->security_info),
		       (int)r->rssi_dbm,
		       (unsigned)r->channel);
	}

	/*
	 * ---------------------------------------------------------------
	 * READING -- plain summary of the two observations this app exists
	 * to make: did the link survive the silence, and did the second
	 * scan return records.
	 * ---------------------------------------------------------------
	 */
	printk("\n=== READING ===\n");
	printk("Link survived the 25 s silence: %s\n", survived_silence ? "YES" : "NO");
	printk("Second scan (STEP 5) returned records: %s (%u record%s)\n",
	       got_records ? "YES" : "NO",
	       (unsigned)count,
	       (count == 1u) ? "" : "s");
	if (survived_silence && got_records) {
		printk("Consistent with mechanism B (the quiesce-cancel race): a silent bus let the "
		       "radio work complete and the role stayed latched.\n");
	} else if (!survived_silence) {
		printk("The bus stayed dead through a completely silent window -- NOT consistent "
		       "with mechanism B alone; the OTHER reading (the radio op itself does not "
		       "return within its bound, independent of host traffic) is not ruled out.\n");
	} else {
		printk("Link survived the silence but the second scan returned no records -- "
		       "inconclusive on whether the role actually latched; re-run against a bench "
		       "with known APs in range before drawing a conclusion.\n");
	}

	return 0;
}
```
